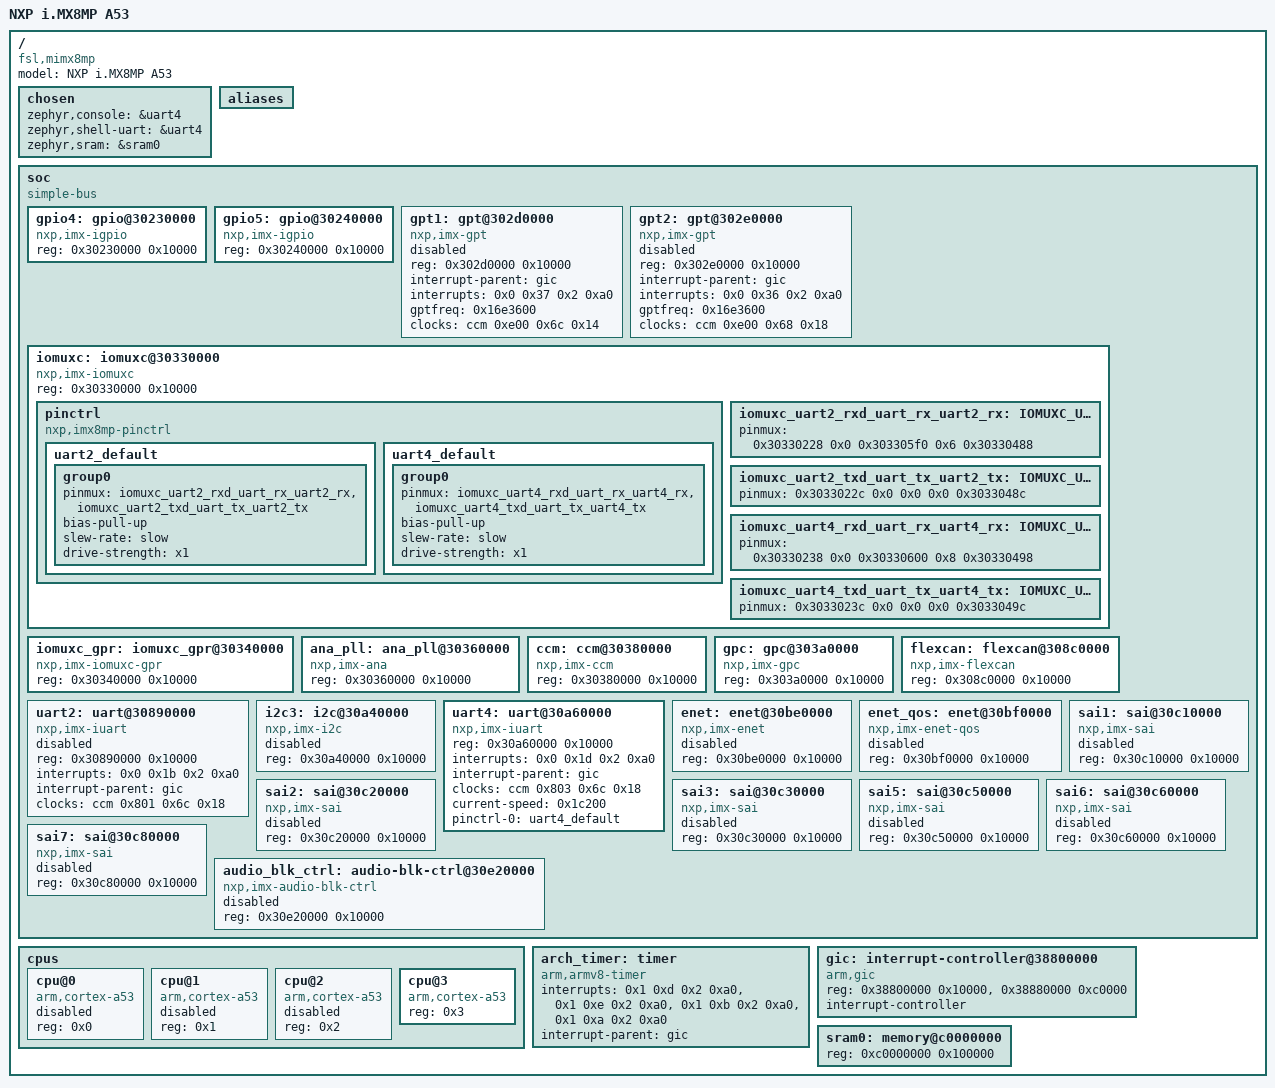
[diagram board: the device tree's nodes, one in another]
/dts-v1/;

/ {
	#address-cells = < 0x1 >;
	#size-cells = < 0x1 >;
	model = "NXP i.MX8MP A53";
	compatible = "fsl,mimx8mp";
	chosen {
		zephyr,console = &uart4;
		zephyr,shell-uart = &uart4;
		zephyr,sram = &sram0;
	};
	aliases {
	};
	soc {
		#address-cells = < 0x1 >;
		#size-cells = < 0x1 >;
		compatible = "simple-bus";
		ranges;
		gpio4: gpio@30230000 {
			compatible = "nxp,imx-igpio";
			reg = < 0x30230000 0x10000 >;
		};
		gpio5: gpio@30240000 {
			compatible = "nxp,imx-igpio";
			reg = < 0x30240000 0x10000 >;
		};
		gpt1: gpt@302d0000 {
			compatible = "nxp,imx-gpt";
			reg = < 0x302d0000 0x10000 >;
			interrupt-parent = < &gic >;
			interrupts = < 0x0 0x37 0x2 0xa0 >;
			gptfreq = < 0x16e3600 >;
			clocks = < &ccm 0xe00 0x6c 0x14 >;
			status = "disabled";
		};
		gpt2: gpt@302e0000 {
			compatible = "nxp,imx-gpt";
			reg = < 0x302e0000 0x10000 >;
			interrupt-parent = < &gic >;
			interrupts = < 0x0 0x36 0x2 0xa0 >;
			gptfreq = < 0x16e3600 >;
			clocks = < &ccm 0xe00 0x68 0x18 >;
			status = "disabled";
		};
		iomuxc: iomuxc@30330000 {
			compatible = "nxp,imx-iomuxc";
			reg = < 0x30330000 0x10000 >;
			status = "okay";
			pinctrl: pinctrl {
				status = "okay";
				compatible = "nxp,imx8mp-pinctrl";
				uart2_default: uart2_default {
					group0 {
						pinmux = < &iomuxc_uart2_rxd_uart_rx_uart2_rx >, < &iomuxc_uart2_txd_uart_tx_uart2_tx >;
						bias-pull-up;
						slew-rate = "slow";
						drive-strength = "x1";
					};
				};
				uart4_default: uart4_default {
					phandle = < 0x7 >;
					group0 {
						pinmux = < &iomuxc_uart4_rxd_uart_rx_uart4_rx >, < &iomuxc_uart4_txd_uart_tx_uart4_tx >;
						bias-pull-up;
						slew-rate = "slow";
						drive-strength = "x1";
					};
				};
			};
			iomuxc_uart2_rxd_uart_rx_uart2_rx: IOMUXC_UART2_RXD_UART_RX_UART2_RX {
				pinmux = < 0x30330228 0x0 0x303305f0 0x6 0x30330488 >;
				phandle = < 0x3 >;
			};
			iomuxc_uart2_txd_uart_tx_uart2_tx: IOMUXC_UART2_TXD_UART_TX_UART2_TX {
				pinmux = < 0x3033022c 0x0 0x0 0x0 0x3033048c >;
				phandle = < 0x4 >;
			};
			iomuxc_uart4_rxd_uart_rx_uart4_rx: IOMUXC_UART4_RXD_UART_RX_UART4_RX {
				pinmux = < 0x30330238 0x0 0x30330600 0x8 0x30330498 >;
				phandle = < 0x5 >;
			};
			iomuxc_uart4_txd_uart_tx_uart4_tx: IOMUXC_UART4_TXD_UART_TX_UART4_TX {
				pinmux = < 0x3033023c 0x0 0x0 0x0 0x3033049c >;
				phandle = < 0x6 >;
			};
		};
		iomuxc_gpr: iomuxc_gpr@30340000 {
			compatible = "nxp,imx-iomuxc-gpr";
			reg = < 0x30340000 0x10000 >;
		};
		ana_pll: ana_pll@30360000 {
			compatible = "nxp,imx-ana";
			reg = < 0x30360000 0x10000 >;
		};
		ccm: ccm@30380000 {
			compatible = "nxp,imx-ccm";
			reg = < 0x30380000 0x10000 >;
			#clock-cells = < 0x3 >;
			phandle = < 0x2 >;
		};
		gpc: gpc@303a0000 {
			compatible = "nxp,imx-gpc";
			reg = < 0x303a0000 0x10000 >;
		};
		flexcan: flexcan@308c0000 {
			compatible = "nxp,imx-flexcan";
			reg = < 0x308c0000 0x10000 >;
		};
		uart2: uart@30890000 {
			compatible = "nxp,imx-iuart";
			reg = < 0x30890000 0x10000 >;
			interrupts = < 0x0 0x1b 0x2 0xa0 >;
			interrupt-names = "irq_0";
			interrupt-parent = < &gic >;
			clocks = < &ccm 0x801 0x6c 0x18 >;
			status = "disabled";
		};
		i2c3: i2c@30a40000 {
			compatible = "nxp,imx-i2c";
			reg = < 0x30a40000 0x10000 >;
			status = "disabled";
		};
		uart4: uart@30a60000 {
			compatible = "nxp,imx-iuart";
			reg = < 0x30a60000 0x10000 >;
			interrupts = < 0x0 0x1d 0x2 0xa0 >;
			interrupt-names = "irq_0";
			interrupt-parent = < &gic >;
			clocks = < &ccm 0x803 0x6c 0x18 >;
			status = "okay";
			current-speed = < 0x1c200 >;
			pinctrl-0 = < &uart4_default >;
			pinctrl-names = "default";
		};
		enet: enet@30be0000 {
			compatible = "nxp,imx-enet";
			reg = < 0x30be0000 0x10000 >;
			status = "disabled";
		};
		enet_qos: enet@30bf0000 {
			compatible = "nxp,imx-enet-qos";
			reg = < 0x30bf0000 0x10000 >;
			status = "disabled";
		};
		sai1: sai@30c10000 {
			compatible = "nxp,imx-sai";
			reg = < 0x30c10000 0x10000 >;
			status = "disabled";
		};
		sai2: sai@30c20000 {
			compatible = "nxp,imx-sai";
			reg = < 0x30c20000 0x10000 >;
			status = "disabled";
		};
		sai3: sai@30c30000 {
			compatible = "nxp,imx-sai";
			reg = < 0x30c30000 0x10000 >;
			status = "disabled";
		};
		sai5: sai@30c50000 {
			compatible = "nxp,imx-sai";
			reg = < 0x30c50000 0x10000 >;
			status = "disabled";
		};
		sai6: sai@30c60000 {
			compatible = "nxp,imx-sai";
			reg = < 0x30c60000 0x10000 >;
			status = "disabled";
		};
		sai7: sai@30c80000 {
			compatible = "nxp,imx-sai";
			reg = < 0x30c80000 0x10000 >;
			status = "disabled";
		};
		audio_blk_ctrl: audio-blk-ctrl@30e20000 {
			compatible = "nxp,imx-audio-blk-ctrl";
			reg = < 0x30e20000 0x10000 >;
			status = "disabled";
		};
	};
	cpus {
		#address-cells = < 0x1 >;
		#size-cells = < 0x0 >;
		cpu@0 {
			device_type = "cpu";
			compatible = "arm,cortex-a53";
			reg = < 0x0 >;
			status = "disabled";
		};
		cpu@1 {
			device_type = "cpu";
			compatible = "arm,cortex-a53";
			reg = < 0x1 >;
			status = "disabled";
		};
		cpu@2 {
			device_type = "cpu";
			compatible = "arm,cortex-a53";
			reg = < 0x2 >;
			status = "disabled";
		};
		cpu@3 {
			device_type = "cpu";
			compatible = "arm,cortex-a53";
			reg = < 0x3 >;
		};
	};
	arch_timer: timer {
		compatible = "arm,armv8-timer";
		interrupts = < 0x1 0xd 0x2 0xa0 >, < 0x1 0xe 0x2 0xa0 >, < 0x1 0xb 0x2 0xa0 >, < 0x1 0xa 0x2 0xa0 >;
		interrupt-parent = < &gic >;
	};
	gic: interrupt-controller@38800000 {
		compatible = "arm,gic";
		reg = < 0x38800000 0x10000 >, < 0x38880000 0xc0000 >;
		interrupt-controller;
		#interrupt-cells = < 0x4 >;
		status = "okay";
		phandle = < 0x1 >;
	};
	sram0: memory@c0000000 {
		reg = < 0xc0000000 0x100000 >;
	};
};
